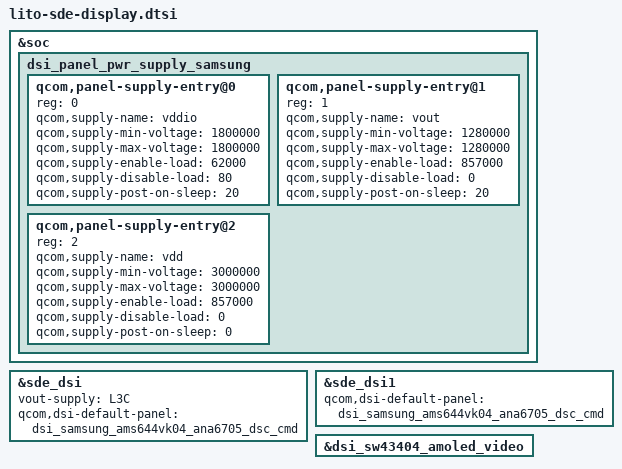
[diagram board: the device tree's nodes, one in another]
#include "../../qcom/lito-sde-display.dtsi"
#include "dsi-panel-samsung_ams644vk04_fhd_dsc.dtsi"
#include "dsi-panel-samsung_ams644vk04_ana6705_fhd_dsc.dtsi"
#include "dsi-panel-samsung_sofef00_m_video.dtsi"

&soc {
	dsi_panel_pwr_supply_samsung: dsi_panel_pwr_supply_samsung {
		#address-cells = <1>;
		#size-cells = <0>;
		qcom,panel-supply-entry@0 {
			reg = <0>;
			qcom,supply-name = "vddio";
			qcom,supply-min-voltage = <1800000>;
			qcom,supply-max-voltage = <1800000>;
			qcom,supply-enable-load = <62000>;
			qcom,supply-disable-load = <80>;
			qcom,supply-post-on-sleep = <20>;
		};

		qcom,panel-supply-entry@1 {
			reg = <1>;
			qcom,supply-name = "vout";
			qcom,supply-min-voltage = <1280000>;
			qcom,supply-max-voltage = <1280000>;
			qcom,supply-enable-load = <857000>;
			qcom,supply-disable-load = <0>;
			qcom,supply-post-on-sleep = <20>;
		};

		qcom,panel-supply-entry@2 {
			reg = <2>;
			qcom,supply-name = "vdd";
			qcom,supply-min-voltage = <3000000>;
			qcom,supply-max-voltage = <3000000>;
			qcom,supply-enable-load = <857000>;
			qcom,supply-disable-load = <0>;
			qcom,supply-post-on-sleep = <0>;
		};
	};

};

&sde_dsi {
	vout-supply = <&L3C>;
	qcom,dsi-default-panel = <&dsi_samsung_ams644vk04_ana6705_dsc_cmd>;
};

&sde_dsi1 {
	/delete-property/ vddio-supply;
	/delete-property/ vdd-supply;
	qcom,dsi-default-panel = <&dsi_samsung_ams644vk04_ana6705_dsc_cmd>;
};

&dsi_sw43404_amoled_video {
	/delete-property/ qcom,mdss-dsi-qsync-min-refresh-rate;
};
